# PIC32MZ0512EFK100 register map
Vendor: Microchip
Registers are 32-bit, read-write, reset 0x0 unless marked. A register's access mark holds for its fields unless they carry their own. Addresses are absolute, and some are shared; only a register's first bit layout is shown; [hi:lo] are bit positions; {n}, {i} and the like mark numbered series.

## PORTD
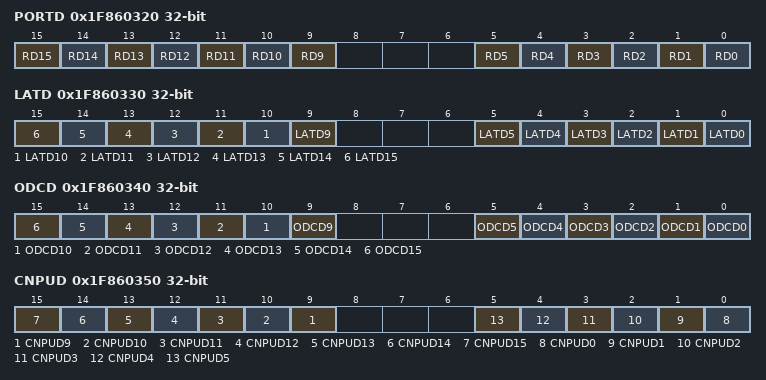
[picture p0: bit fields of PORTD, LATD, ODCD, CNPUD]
0x1F860320 PORTD reset not defined — (power-on value ----------------xxxxxxx---xxxxxx)
  [n] RD{n} (n=9..15), [n] RD{n} (n=0..5)
0x1F860330 LATD reset not defined — (power-on value ----------------xxxxxxx---xxxxxx)
  [n] LATD{n} (n=9..15), [n] LATD{n} (n=0..5)
0x1F860340 ODCD
  [n] ODCD{n} (n=9..15), [n] ODCD{n} (n=0..5)
0x1F860350 CNPUD
  [n] CNPUD{n} (n=9..15), [n] CNPUD{n} (n=0..5)
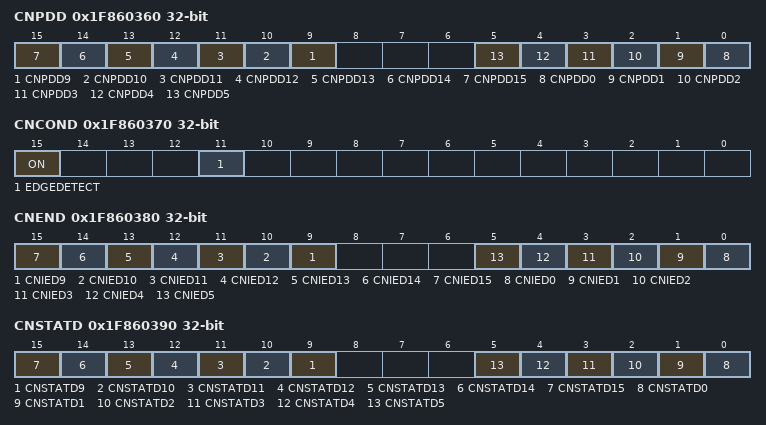
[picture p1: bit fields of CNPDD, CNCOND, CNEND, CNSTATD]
0x1F860360 CNPDD
  [n] CNPDD{n} (n=9..15), [n] CNPDD{n} (n=0..5)
0x1F860370 CNCOND
  [15] ON, [11] EDGEDETECT
0x1F860380 CNEND
  [n] CNIED{n} (n=9..15), [n] CNIED{n} (n=0..5)
0x1F860390 CNSTATD
  [n] CNSTATD{n} (n=9..15), [n] CNSTATD{n} (n=0..5)
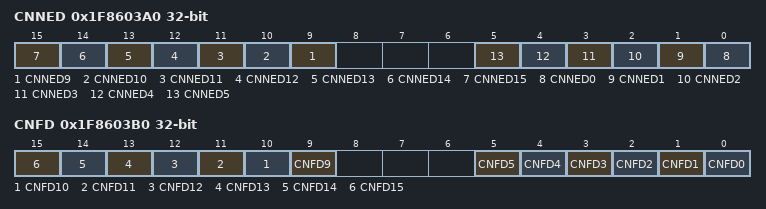
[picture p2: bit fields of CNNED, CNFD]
0x1F8603A0 CNNED
  [n] CNNED{n} (n=9..15), [n] CNNED{n} (n=0..5)
0x1F8603B0 CNFD
  [n] CNFD{n} (n=9..15), [n] CNFD{n} (n=0..5)

## PORTE
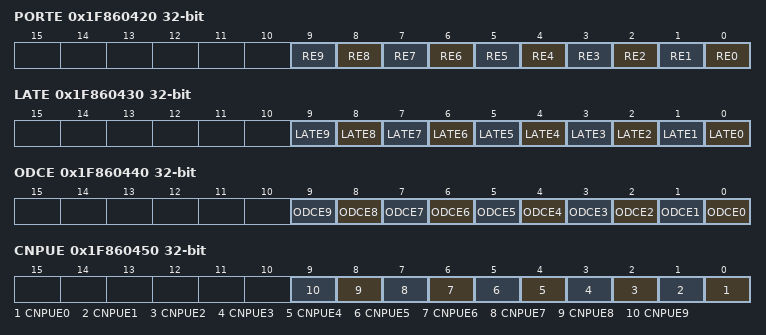
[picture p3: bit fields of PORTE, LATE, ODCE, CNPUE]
0x1F860420 PORTE reset not defined — (power-on value ----------------------xxxxxxxxxx)
  [n] RE{n} (n=0..9)
0x1F860430 LATE reset not defined — (power-on value ----------------------xxxxxxxxxx)
  [n] LATE{n} (n=0..9)
0x1F860440 ODCE
  [n] ODCE{n} (n=0..9)
0x1F860450 CNPUE
  [n] CNPUE{n} (n=0..9)
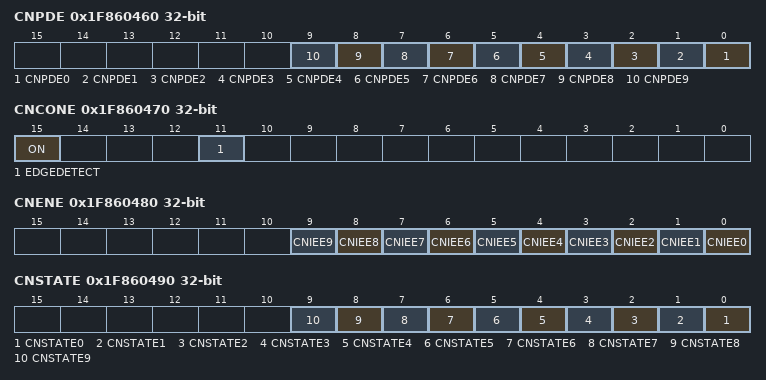
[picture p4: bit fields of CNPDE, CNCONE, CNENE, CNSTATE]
0x1F860460 CNPDE
  [n] CNPDE{n} (n=0..9)
0x1F860470 CNCONE
  [15] ON, [11] EDGEDETECT
0x1F860480 CNENE
  [n] CNIEE{n} (n=0..9)
0x1F860490 CNSTATE
  [n] CNSTATE{n} (n=0..9)
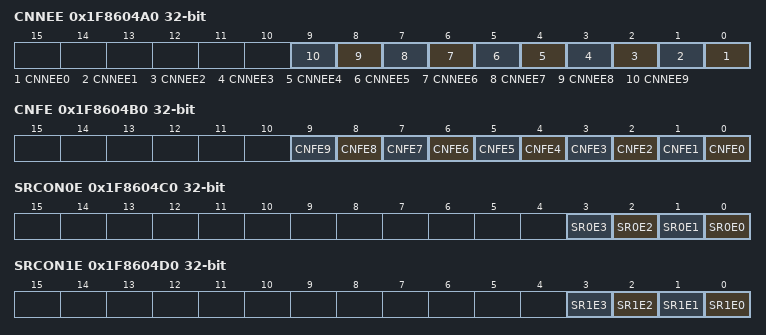
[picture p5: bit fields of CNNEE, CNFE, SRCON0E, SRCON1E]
0x1F8604A0 CNNEE
  [n] CNNEE{n} (n=0..9)
0x1F8604B0 CNFE
  [n] CNFE{n} (n=0..9)
0x1F8604C0 SRCON0E
  [n] SR0E{n} (n=0..3)
0x1F8604D0 SRCON1E
  [n] SR1E{n} (n=0..3)

## PORTF
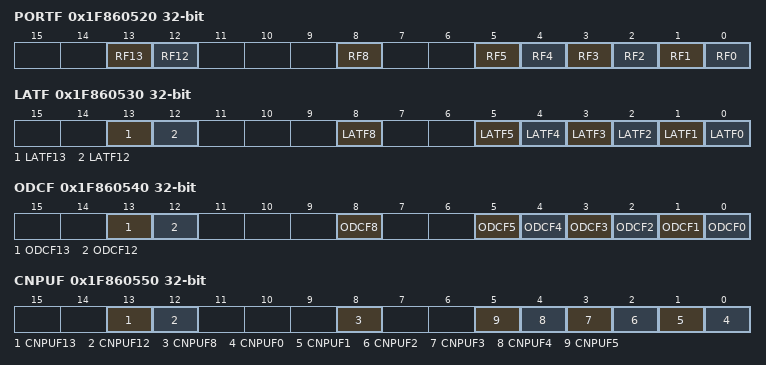
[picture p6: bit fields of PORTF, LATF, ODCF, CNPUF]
0x1F860520 PORTF reset not defined — (power-on value ------------------xx---x--xxxxxx)
  [13] RF13, [12] RF12, [8] RF8, [n] RF{n} (n=0..5)
0x1F860530 LATF reset not defined — (power-on value ------------------xx---x--xxxxxx)
  [13] LATF13, [12] LATF12, [8] LATF8, [n] LATF{n} (n=0..5)
0x1F860540 ODCF
  [13] ODCF13, [12] ODCF12, [8] ODCF8, [n] ODCF{n} (n=0..5)
0x1F860550 CNPUF
  [13] CNPUF13, [12] CNPUF12, [8] CNPUF8, [n] CNPUF{n} (n=0..5)
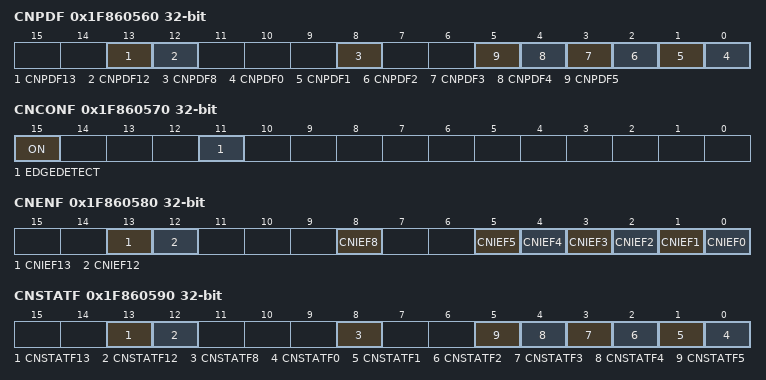
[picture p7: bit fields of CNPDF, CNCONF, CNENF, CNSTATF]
0x1F860560 CNPDF
  [13] CNPDF13, [12] CNPDF12, [8] CNPDF8, [n] CNPDF{n} (n=0..5)
0x1F860570 CNCONF
  [15] ON, [11] EDGEDETECT
0x1F860580 CNENF
  [13] CNIEF13, [12] CNIEF12, [8] CNIEF8, [n] CNIEF{n} (n=0..5)
0x1F860590 CNSTATF
  [13] CNSTATF13, [12] CNSTATF12, [8] CNSTATF8, [n] CNSTATF{n} (n=0..5)
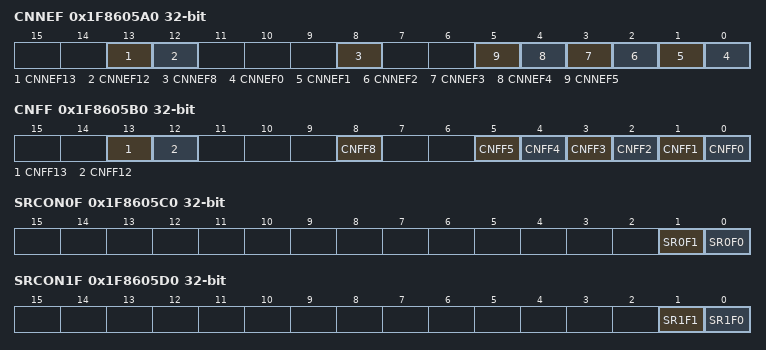
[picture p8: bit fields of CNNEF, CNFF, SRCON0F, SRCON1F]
0x1F8605A0 CNNEF
  [13] CNNEF13, [12] CNNEF12, [8] CNNEF8, [n] CNNEF{n} (n=0..5)
0x1F8605B0 CNFF
  [13] CNFF13, [12] CNFF12, [8] CNFF8, [n] CNFF{n} (n=0..5)
0x1F8605C0 SRCON0F
  [1] SR0F1, [0] SR0F0
0x1F8605D0 SRCON1F
  [1] SR1F1, [0] SR1F0

## PORTG
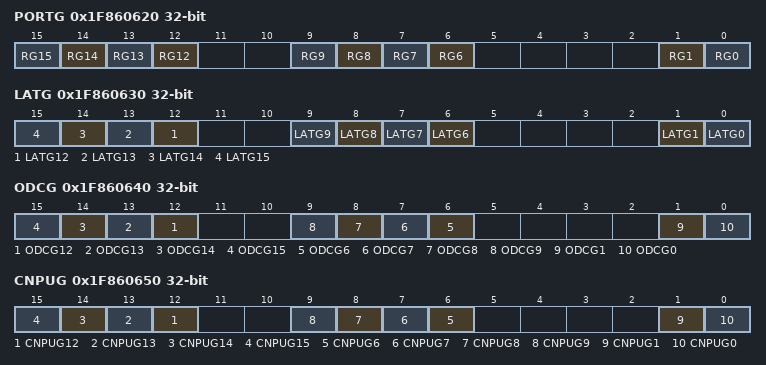
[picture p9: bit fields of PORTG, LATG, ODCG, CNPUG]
0x1F860620 PORTG reset not defined — (power-on value ----------------xxxx--xxxx----xx)
  [n] RG{n} (n=12..15), [n] RG{n} (n=6..9), [1] RG1, [0] RG0
0x1F860630 LATG reset not defined — (power-on value ----------------xxxx--xxxx----xx)
  [n] LATG{n} (n=12..15), [n] LATG{n} (n=6..9), [1] LATG1, [0] LATG0
0x1F860640 ODCG
  [n] ODCG{n} (n=12..15), [n] ODCG{n} (n=6..9), [1] ODCG1, [0] ODCG0
0x1F860650 CNPUG
  [n] CNPUG{n} (n=12..15), [n] CNPUG{n} (n=6..9), [1] CNPUG1, [0] CNPUG0
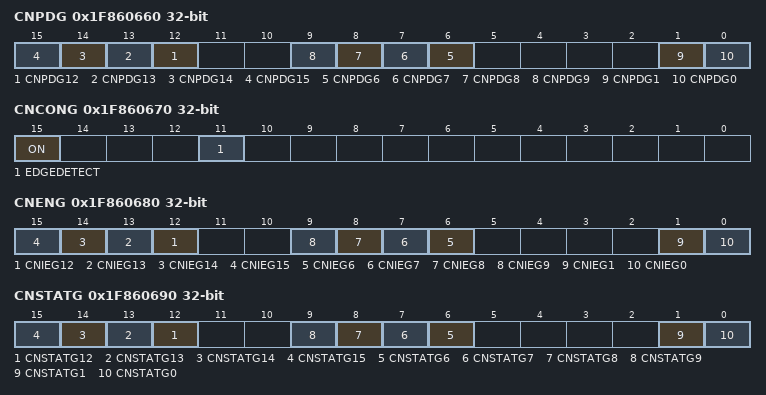
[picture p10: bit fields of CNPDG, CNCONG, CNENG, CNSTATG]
0x1F860660 CNPDG
  [n] CNPDG{n} (n=12..15), [n] CNPDG{n} (n=6..9), [1] CNPDG1, [0] CNPDG0
0x1F860670 CNCONG
  [15] ON, [11] EDGEDETECT
0x1F860680 CNENG
  [n] CNIEG{n} (n=12..15), [n] CNIEG{n} (n=6..9), [1] CNIEG1, [0] CNIEG0
0x1F860690 CNSTATG
  [n] CNSTATG{n} (n=12..15), [n] CNSTATG{n} (n=6..9), [1] CNSTATG1, [0] CNSTATG0
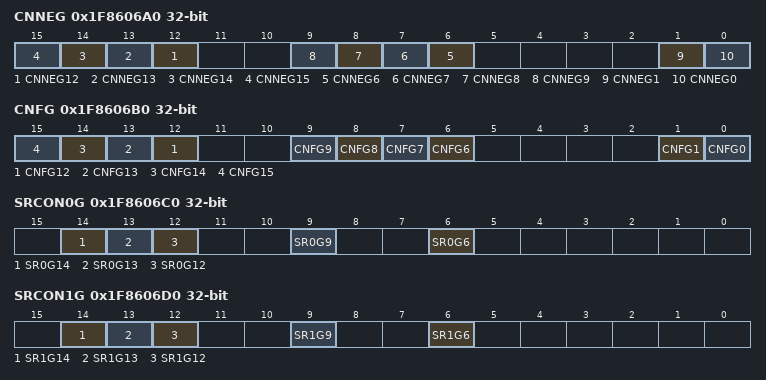
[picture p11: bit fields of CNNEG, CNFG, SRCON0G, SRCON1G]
0x1F8606A0 CNNEG
  [n] CNNEG{n} (n=12..15), [n] CNNEG{n} (n=6..9), [1] CNNEG1, [0] CNNEG0
0x1F8606B0 CNFG
  [n] CNFG{n} (n=12..15), [n] CNFG{n} (n=6..9), [1] CNFG1, [0] CNFG0
0x1F8606C0 SRCON0G
  [14] SR0G14, [13] SR0G13, [12] SR0G12, [9] SR0G9, [6] SR0G6
0x1F8606D0 SRCON1G
  [14] SR1G14, [13] SR1G13, [12] SR1G12, [9] SR1G9, [6] SR1G6

## CAN1
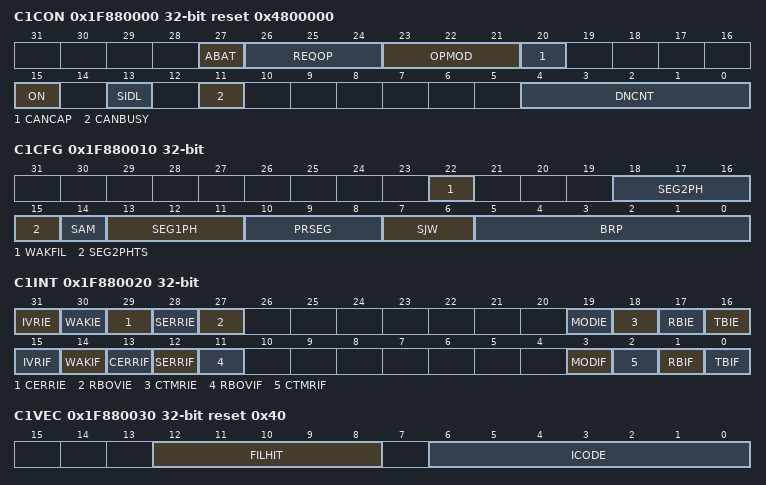
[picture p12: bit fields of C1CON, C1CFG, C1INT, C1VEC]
0x1F880000 C1CON reset 0x4800000
  [27] ABAT — (can only be set)
  [26:24] REQOP
  [23:21] OPMOD ro
  [20] CANCAP
  [15] ON
  [13] SIDL
  [11] CANBUSY ro
  [4:0] DNCNT
0x1F880010 C1CFG
  [22] WAKFIL, [18:16] SEG2PH, [15] SEG2PHTS, [14] SAM, [13:11] SEG1PH, [10:8] PRSEG, [7:6] SJW, [5:0] BRP
0x1F880020 C1INT
  [31] IVRIE, [30] WAKIE, [29] CERRIE, [28] SERRIE, [27] RBOVIE, [19] MODIE, [18] CTMRIE, [17] RBIE, [16] TBIE, [15] IVRIF, [14] WAKIF, [13] CERRIF, [12] SERRIF, [11] RBOVIF, [3] MODIF, [2] CTMRIF, [1] RBIF, [0] TBIF
0x1F880030 C1VEC ro reset 0x40
  [12:8] FILHIT, [6:0] ICODE
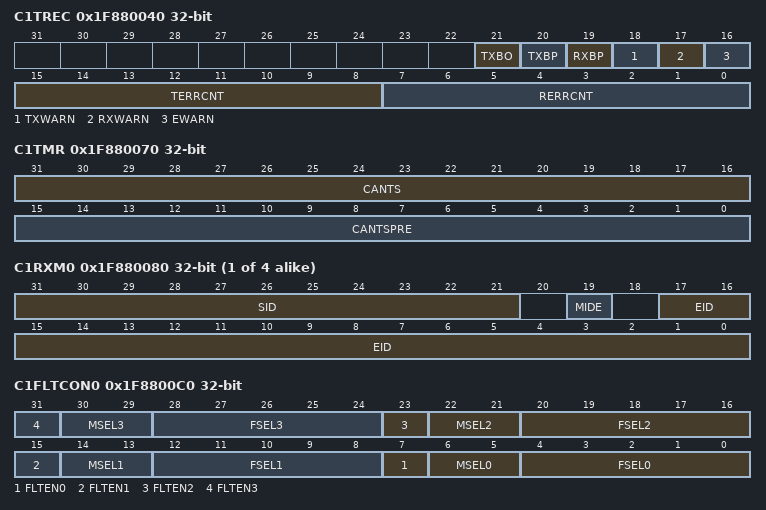
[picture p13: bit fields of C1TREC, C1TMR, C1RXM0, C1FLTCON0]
0x1F880040 C1TREC ro
  [21] TXBO, [20] TXBP, [19] RXBP, [18] TXWARN, [17] RXWARN, [16] EWARN, [15:8] TERRCNT, [7:0] RERRCNT
0x1F880050 C1FSTAT ro
  [31:0] FIFOIP
0x1F880060 C1RXOVF ro
  [31:0] RXOVF
0x1F880070 C1TMR
  [31:16] CANTS, [15:0] CANTSPRE
{0x1F880080+0x10*i} C1RXM{i} (i=0..3)
  [31:21] SID, [19] MIDE, [17:0] EID
0x1F8800C0 C1FLTCON0
  [8n+7] FLTEN{n} (n=0..3), [8n+6:8n+5] MSEL{n} (n=0..3), [8n+4:8n] FSEL{n} (n=0..3)
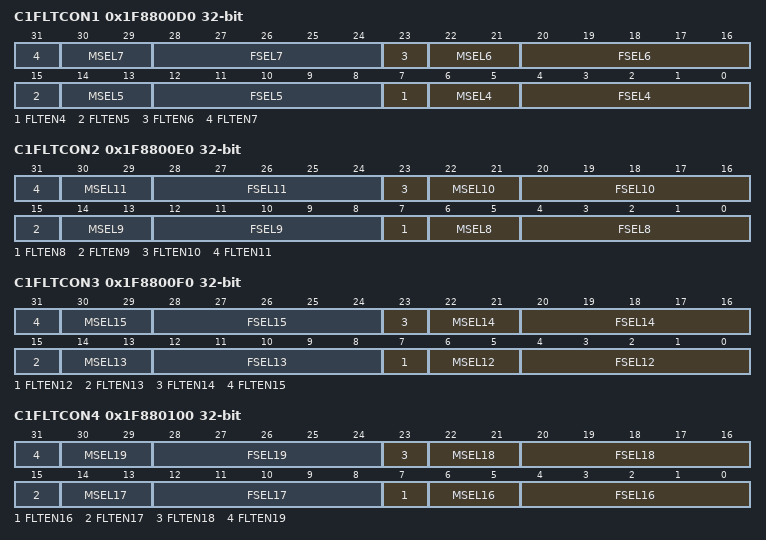
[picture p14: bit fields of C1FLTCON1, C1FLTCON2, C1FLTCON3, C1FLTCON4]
0x1F8800D0 C1FLTCON1
  [8n-25] FLTEN{n} (n=4..7), [8n-26:8n-27] MSEL{n} (n=4..7), [8n-28:8n-32] FSEL{n} (n=4..7)
0x1F8800E0 C1FLTCON2
  [8n-57] FLTEN{n} (n=8..11), [8n-58:8n-59] MSEL{n} (n=8..11), [8n-60:8n-64] FSEL{n} (n=8..11)
0x1F8800F0 C1FLTCON3
  [8n-89] FLTEN{n} (n=12..15), [8n-90:8n-91] MSEL{n} (n=12..15), [8n-92:8n-96] FSEL{n} (n=12..15)
0x1F880100 C1FLTCON4
  [8n-121] FLTEN{n} (n=16..19), [8n-122:8n-123] MSEL{n} (n=16..19), [8n-124:8n-128] FSEL{n} (n=16..19)
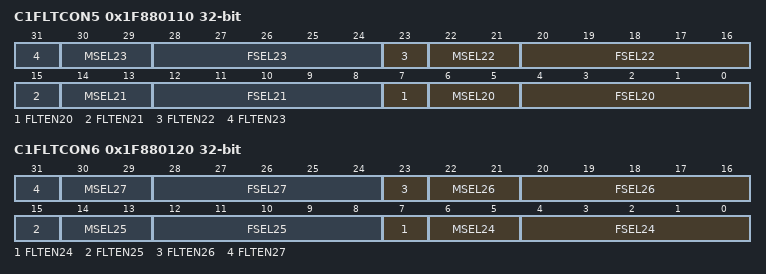
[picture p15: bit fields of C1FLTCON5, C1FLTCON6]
0x1F880110 C1FLTCON5
  [8n-153] FLTEN{n} (n=20..23), [8n-154:8n-155] MSEL{n} (n=20..23), [8n-156:8n-160] FSEL{n} (n=20..23)
0x1F880120 C1FLTCON6
  [8n-185] FLTEN{n} (n=24..27), [8n-186:8n-187] MSEL{n} (n=24..27), [8n-188:8n-192] FSEL{n} (n=24..27)
0x1F880130 C1FLTCON7
  [8n-217] FLTEN{n} (n=28..31), [8n-218:8n-219] MSEL{n} (n=28..31), [8n-220:8n-224] FSEL{n} (n=28..31)
{0x1F880140+0x10*i} C1RXF{i} reset not defined (i=0..31) — (power-on value xxxxxxxxxxx0x0xxxxxxxxxxxxxxxxxx)
  [31:21] SID, [19] EXID, [17:0] EID
0x1F880340 C1FIFOBA
  [31:2] FIFOBA
{0x1F880350+0x40*i} C1FIFOCON{i} (i=0..31)
  [20:16] FSIZE, [14] FRESET, [13] UINC, [12] DONLY, [7] TXEN, [6] TXABAT, [5] TXLARB, [4] TXERR, [3] TXREQ, [2] RTREN, [1:0] TXPRI
{0x1F880360+0x40*i} C1FIFOINT{i} (i=0..31)
  [26] TXNFULLIE, [25] TXHALFIE, [24] TXEMPTYIE, [19] RXOVFLIE, [18] RXFULLIE, [17] RXHALFIE, [16] RXNEMPTYIE, [10] TXNFULLIF ro, [9] TXHALFIF ro, [8] TXEMPTYIF ro, [3] RXOVFLIF, [2] RXFULLIF ro, [1] RXHALFIF ro, [0] RXNEMPTYIF ro
{0x1F880370+0x40*i} C1FIFOUA{i} ro reset not defined (i=0..31) — (power-on value xxxxxxxxxxxxxxxxxxxxxxxxxxxxxx00)
  [31:2] FIFOUA
{0x1F880380+0x40*i} C1FIFOCI{i} ro (i=0..31)
  [4:0] CFIFOCI
